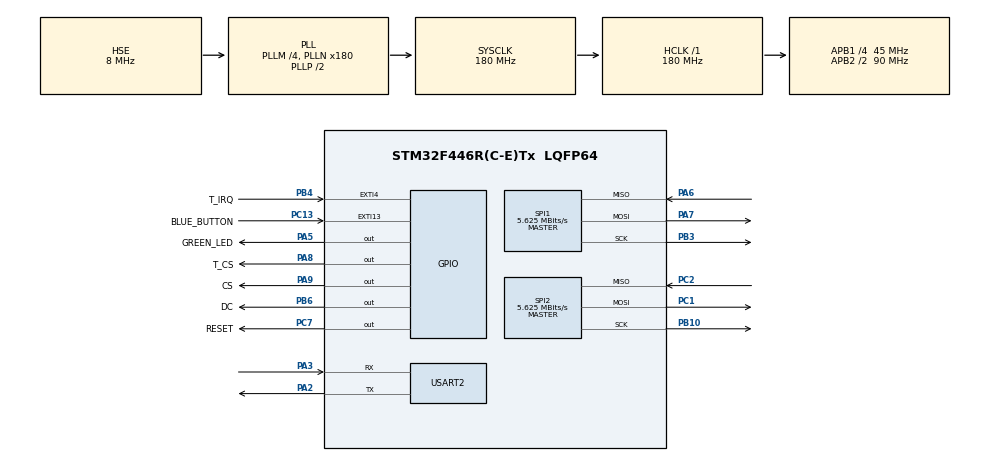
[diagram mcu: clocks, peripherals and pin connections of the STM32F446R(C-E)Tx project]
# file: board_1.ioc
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Dma.Request0=SPI1_TX
Dma.Request1=USART2_RX
Dma.Request2=USART2_TX
Dma.Request3=SPI2_RX
Dma.SPI1_TX.0.Direction=DMA_MEMORY_TO_PERIPH
Dma.SPI1_TX.0.FIFOMode=DMA_FIFOMODE_DISABLE
Dma.SPI1_TX.0.Instance=DMA2_Stream3
Dma.SPI1_TX.0.MemDataAlignment=DMA_MDATAALIGN_BYTE
Dma.SPI1_TX.0.MemInc=DMA_MINC_ENABLE
Dma.SPI1_TX.0.Mode=DMA_NORMAL
Dma.SPI1_TX.0.PeriphDataAlignment=DMA_PDATAALIGN_BYTE
Dma.SPI1_TX.0.PeriphInc=DMA_PINC_DISABLE
Dma.SPI1_TX.0.Priority=DMA_PRIORITY_LOW
Dma.SPI2_RX.3.Direction=DMA_PERIPH_TO_MEMORY
Dma.SPI2_RX.3.FIFOMode=DMA_FIFOMODE_DISABLE
Dma.SPI2_RX.3.Instance=DMA1_Stream3
Dma.SPI2_RX.3.MemDataAlignment=DMA_MDATAALIGN_BYTE
Dma.SPI2_RX.3.MemInc=DMA_MINC_ENABLE
Dma.SPI2_RX.3.Mode=DMA_NORMAL
Dma.SPI2_RX.3.PeriphDataAlignment=DMA_PDATAALIGN_BYTE
Dma.SPI2_RX.3.PeriphInc=DMA_PINC_DISABLE
Dma.SPI2_RX.3.Priority=DMA_PRIORITY_LOW
Dma.USART2_RX.1.Direction=DMA_PERIPH_TO_MEMORY
Dma.USART2_RX.1.FIFOMode=DMA_FIFOMODE_DISABLE
Dma.USART2_RX.1.Instance=DMA1_Stream5
Dma.USART2_RX.1.MemDataAlignment=DMA_MDATAALIGN_BYTE
Dma.USART2_RX.1.MemInc=DMA_MINC_ENABLE
Dma.USART2_RX.1.Mode=DMA_NORMAL
Dma.USART2_RX.1.PeriphDataAlignment=DMA_PDATAALIGN_BYTE
Dma.USART2_RX.1.PeriphInc=DMA_PINC_DISABLE
Dma.USART2_RX.1.Priority=DMA_PRIORITY_LOW
Dma.USART2_TX.2.Direction=DMA_MEMORY_TO_PERIPH
Dma.USART2_TX.2.FIFOMode=DMA_FIFOMODE_DISABLE
Dma.USART2_TX.2.Instance=DMA1_Stream6
Dma.USART2_TX.2.MemDataAlignment=DMA_MDATAALIGN_BYTE
Dma.USART2_TX.2.MemInc=DMA_MINC_ENABLE
Dma.USART2_TX.2.Mode=DMA_NORMAL
Dma.USART2_TX.2.PeriphDataAlignment=DMA_PDATAALIGN_BYTE
Dma.USART2_TX.2.PeriphInc=DMA_PINC_DISABLE
Dma.USART2_TX.2.Priority=DMA_PRIORITY_LOW
FREERTOS.Tasks01=normalTask,24,128,startNormalTask,Default,NULL,Dynamic,NULL,NULL
FREERTOS.configTOTAL_HEAP_SIZE=32768
Mcu.Family=STM32F4
Mcu.Name=STM32F446R(C-E)Tx
Mcu.Package=LQFP64
NVIC.DMA1_Stream3_IRQn=true\:5\:0\:false\:false\:true\:true\:false\:true\:true
NVIC.DMA1_Stream5_IRQn=true\:5\:0\:false\:false\:true\:true\:false\:true\:true
NVIC.DMA1_Stream6_IRQn=true\:5\:0\:false\:false\:true\:true\:false\:true\:true
NVIC.DMA2_Stream3_IRQn=true\:5\:0\:false\:false\:true\:true\:false\:true\:true
NVIC.EXTI15_10_IRQn=true\:5\:0\:false\:false\:true\:true\:true\:true\:true
NVIC.EXTI4_IRQn=true\:5\:0\:false\:false\:true\:true\:true\:true\:true
NVIC.PriorityGroup=NVIC_PRIORITYGROUP_4
NVIC.SPI1_IRQn=true\:5\:0\:false\:false\:true\:true\:true\:true\:true
NVIC.SPI2_IRQn=true\:5\:0\:false\:false\:true\:true\:true\:true\:true
NVIC.TIM6_DAC_IRQn=true\:15\:0\:false\:false\:true\:false\:false\:true\:true
NVIC.TimeBase=TIM6_DAC_IRQn
NVIC.TimeBaseIP=TIM6
NVIC.USART2_IRQn=true\:5\:0\:false\:false\:true\:true\:true\:true\:true
PA13.Mode=Serial_Wire
PA13.Signal=SYS_JTMS-SWDIO
PA14.Mode=Serial_Wire
PA14.Signal=SYS_JTCK-SWCLK
PA2.Mode=Asynchronous
PA2.Signal=USART2_TX
PA3.Mode=Asynchronous
PA3.Signal=USART2_RX
PA5.GPIO_Label=GREEN_LED
PA5.Signal=GPIO_Output
PA6.Mode=Full_Duplex_Master
PA6.Signal=SPI1_MISO
PA7.Mode=Full_Duplex_Master
PA7.Signal=SPI1_MOSI
PA8.GPIO_Label=T_CS
PA8.PinState=GPIO_PIN_SET
PA8.Signal=GPIO_Output
PA9.GPIO_Label=CS
PA9.PinState=GPIO_PIN_SET
PA9.Signal=GPIO_Output
PB10.Mode=Full_Duplex_Master
PB10.Signal=SPI2_SCK
PB3.Mode=Full_Duplex_Master
PB3.Signal=SPI1_SCK
PB4.GPIO_Label=T_IRQ
PB4.GPIO_ModeDefaultEXTI=GPIO_MODE_IT_FALLING
PB4.Signal=GPXTI4
PB6.GPIO_Label=DC
PB6.Signal=GPIO_Output
PC1.Mode=Full_Duplex_Master
PC1.Signal=SPI2_MOSI
PC13.GPIO_Label=BLUE_BUTTON
PC13.GPIO_ModeDefaultEXTI=GPIO_MODE_IT_FALLING
PC13.Signal=GPXTI13
PC14-OSC32_IN.Mode=LSE-External-Oscillator
PC14-OSC32_IN.Signal=RCC_OSC32_IN
PC15-OSC32_OUT.Mode=LSE-External-Oscillator
PC15-OSC32_OUT.Signal=RCC_OSC32_OUT
PC2.Mode=Full_Duplex_Master
PC2.Signal=SPI2_MISO
PC7.GPIO_Label=RESET
PC7.Signal=GPIO_Output
PH0-OSC_IN.Mode=HSE-External-Oscillator
PH0-OSC_IN.Signal=RCC_OSC_IN
PH1-OSC_OUT.Mode=HSE-External-Oscillator
PH1-OSC_OUT.Signal=RCC_OSC_OUT
ProjectManager.HeapSize=0x200
ProjectManager.StackSize=0x400
ProjectManager.TargetToolchain=CMake
RCC.AHBFreq_Value=180000000
RCC.APB1CLKDivider=RCC_HCLK_DIV4
RCC.APB1Freq_Value=45000000
RCC.APB1TimFreq_Value=90000000
RCC.APB2CLKDivider=RCC_HCLK_DIV2
RCC.APB2Freq_Value=90000000
RCC.APB2TimFreq_Value=180000000
RCC.CortexFreq_Value=180000000
RCC.HCLKFreq_Value=180000000
RCC.HSE_VALUE=8000000
RCC.PLLM=4
RCC.PLLN=180
RCC.PLLSourceVirtual=RCC_PLLSOURCE_HSE
RCC.RCC_RTC_Clock_SourceVirtual=RCC_RTCCLKSOURCE_LSE
RCC.SYSCLKFreq_VALUE=180000000
RCC.SYSCLKSource=RCC_SYSCLKSOURCE_PLLCLK
RCC.USBFreq_Value=180000000
RCC.VCOOutputFreq_Value=360000000
RTC.Date=12
RTC.Hours=9
RTC.Minutes=11
RTC.Month=RTC_MONTH_AUGUST
RTC.Year=25
SPI1.BaudRatePrescaler=SPI_BAUDRATEPRESCALER_16
SPI1.CalculateBaudRate=5.625 MBits/s
SPI1.Direction=SPI_DIRECTION_2LINES
SPI1.Mode=SPI_MODE_MASTER
SPI1.VirtualType=VM_MASTER
SPI2.BaudRatePrescaler=SPI_BAUDRATEPRESCALER_8
SPI2.CalculateBaudRate=5.625 MBits/s
SPI2.Direction=SPI_DIRECTION_2LINES
SPI2.Mode=SPI_MODE_MASTER
SPI2.VirtualType=VM_MASTER
STMicroelectronics.X-CUBE-TOUCHGFX.4.26.1.ApplicationCcGraphicsJjApplication=TouchGFXOoGenerator
STMicroelectronics.X-CUBE-TOUCHGFX.4.26.1.tgfx_block_size=10240
STMicroelectronics.X-CUBE-TOUCHGFX.4.26.1.tgfx_buffering_strategy=Partial
STMicroelectronics.X-CUBE-TOUCHGFX.4.26.1.tgfx_custom_height=240
STMicroelectronics.X-CUBE-TOUCHGFX.4.26.1.tgfx_custom_width=320
STMicroelectronics.X-CUBE-TOUCHGFX.4.26.1_IsPackSelfContextualization=true
USART2.VirtualMode=VM_ASYNC
VP_CRC_VS_CRC.Mode=CRC_Activate
VP_FREERTOS_VS_CMSIS_V2.Mode=CMSIS_V2
VP_IWDG_VS_IWDG.Mode=IWDG_Activate
VP_RTC_VS_RTC_Activate.Mode=RTC_Enabled
VP_RTC_VS_RTC_Calendar.Mode=RTC_Calendar
VP_STMicroelectronics.X-CUBE-TOUCHGFX_VS_GraphicsJjApplication_4.26.1.Mode=GraphicsJjApplication
VP_SYS_VS_tim6.Mode=TIM6
board=custom

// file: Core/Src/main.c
/* USER CODE BEGIN Header */
/**
  ******************************************************************************
  * @file           : main.c
  * @brief          : Main program body
  ******************************************************************************
  * @attention
  *
  * Copyright (c) 2025 STMicroelectronics.
  * All rights reserved.
  *
  * This software is licensed under terms that can be found in the LICENSE file
  * in the root directory of this software component.
  * If no LICENSE file comes with this software, it is provided AS-IS.
  *
  ******************************************************************************
  */
/* USER CODE END Header */
#include "main.h"
#include "cmsis_os.h"
#include "crc.h"
#include "dma.h"
#include "iwdg.h"
#include "rtc.h"
#include "spi.h"
#include "usart.h"
#include "gpio.h"
#include "app_touchgfx.h"

/* USER CODE BEGIN Includes */
#include "app_main.h"

/* USER CODE END Includes */

void SystemClock_Config(void);
void MX_FREERTOS_Init(void);

int main(void)
{

  /* USER CODE BEGIN 1 */
  // Super early blink to confirm code is running at all
  RCC->AHB1ENR |= RCC_AHB1ENR_GPIOAEN;
  GPIOA->MODER &= ~(3U << (5 * 2));
  GPIOA->MODER |= (1U << (5 * 2));
  for(int i=0; i<20; i++) {
    GPIOA->ODR ^= (1U << 5);
    for(volatile int j=0; j<100000; j++);
  }
  /* USER CODE END 1 */

  /* MCU Configuration--------------------------------------------------------*/

  /* Reset of all peripherals, Initializes the Flash interface and the Systick. */
  HAL_Init();

  /* Configure the system clock */
  SystemClock_Config();

  /* Initialize all configured peripherals */
  MX_GPIO_Init();
  MX_DMA_Init();
  MX_SPI1_Init();
  MX_RTC_Init();
  MX_SPI2_Init();
  MX_USART2_UART_Init();
  MX_CRC_Init();
  MX_IWDG_Init();
  MX_TouchGFX_Init();
  /* Call PreOsInit function */
  MX_TouchGFX_PreOSInit();
  /* USER CODE BEGIN 2 */
  /* DRV_Setup() runs at the top of the TouchGFX task (App/app_main.c), not
   * here: it uses HAL_Delay, and the first FreeRTOS API call (already made
   * above by MX_TouchGFX_Init) masks interrupts (BASEPRI) until
   * osKernelStart(), which freezes the HAL tick and deadlocks any pre-kernel
   * HAL_Delay. */
  /* USER CODE END 2 */

  /* Init scheduler */
  osKernelInitialize();  /* Call init function for freertos objects (in cmsis_os2.c) */
  MX_FREERTOS_Init();

  /* Start scheduler */
  osKernelStart();

  /* We should never get here as control is now taken by the scheduler */

  /* Infinite loop */
  while (1)
  {

  }
}

void SystemClock_Config(void)
{
  RCC_OscInitTypeDef RCC_OscInitStruct = {0};
  RCC_ClkInitTypeDef RCC_ClkInitStruct = {0};

  /** Configure the main internal regulator output voltage
  */
  __HAL_RCC_PWR_CLK_ENABLE();
  __HAL_PWR_VOLTAGESCALING_CONFIG(PWR_REGULATOR_VOLTAGE_SCALE1);

  /** Initializes the RCC Oscillators according to the specified parameters
  * in the RCC_OscInitTypeDef structure.
  */
  RCC_OscInitStruct.OscillatorType = RCC_OSCILLATORTYPE_LSI|RCC_OSCILLATORTYPE_HSE
                              |RCC_OSCILLATORTYPE_LSE;
  RCC_OscInitStruct.HSEState = RCC_HSE_ON;
  RCC_OscInitStruct.LSEState = RCC_LSE_ON;
  RCC_OscInitStruct.LSIState = RCC_LSI_ON;
  RCC_OscInitStruct.PLL.PLLState = RCC_PLL_ON;
  RCC_OscInitStruct.PLL.PLLSource = RCC_PLLSOURCE_HSE;
  RCC_OscInitStruct.PLL.PLLM = 4;
  RCC_OscInitStruct.PLL.PLLN = 180;
  RCC_OscInitStruct.PLL.PLLP = RCC_PLLP_DIV2;
  RCC_OscInitStruct.PLL.PLLQ = 2;
  RCC_OscInitStruct.PLL.PLLR = 2;
  if (HAL_RCC_OscConfig(&RCC_OscInitStruct) != HAL_OK)
  {
    Error_Handler();
  }

  /** Activate the Over-Drive mode
  */
  if (HAL_PWREx_EnableOverDrive() != HAL_OK)
  {
    Error_Handler();
  }

  /** Initializes the CPU, AHB and APB buses clocks
  */
  RCC_ClkInitStruct.ClockType = RCC_CLOCKTYPE_HCLK|RCC_CLOCKTYPE_SYSCLK
                              |RCC_CLOCKTYPE_PCLK1|RCC_CLOCKTYPE_PCLK2;
  RCC_ClkInitStruct.SYSCLKSource = RCC_SYSCLKSOURCE_PLLCLK;
  RCC_ClkInitStruct.AHBCLKDivider = RCC_SYSCLK_DIV1;
  RCC_ClkInitStruct.APB1CLKDivider = RCC_HCLK_DIV4;
  RCC_ClkInitStruct.APB2CLKDivider = RCC_HCLK_DIV2;

  if (HAL_RCC_ClockConfig(&RCC_ClkInitStruct, FLASH_LATENCY_5) != HAL_OK)
  {
    Error_Handler();
  }
}

void HAL_TIM_PeriodElapsedCallback(TIM_HandleTypeDef *htim)
{
  if (htim->Instance == TIM6)
  {
    HAL_IncTick();
  }
}

void Error_Handler(void)
{
  __disable_irq();
  while (1)
  {
  }
}

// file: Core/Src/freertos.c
/* USER CODE BEGIN Header */
/**
  ******************************************************************************
  * File Name          : freertos.c
  * Description        : Code for freertos applications
  ******************************************************************************
  * @attention
  *
  * Copyright (c) 2025 STMicroelectronics.
  * All rights reserved.
  *
  * This software is licensed under terms that can be found in the LICENSE file
  * in the root directory of this software component.
  * If no LICENSE file comes with this software, it is provided AS-IS.
  *
  ******************************************************************************
  */
/* USER CODE END Header */

#include "FreeRTOS.h"
#include "task.h"
#include "main.h"
#include "cmsis_os.h"

/* USER CODE BEGIN Includes */
#include "app_main.h"
/* USER CODE END Includes */

/* Definitions for normalTask */
osThreadId_t normalTaskHandle;
const osThreadAttr_t normalTask_attributes = {
  .name = "normalTask",
  .stack_size = 128 * 4,
  .priority = (osPriority_t) osPriorityNormal,
};

void startNormalTask(void *argument);

void MX_FREERTOS_Init(void); /* (MISRA C 2004 rule 8.1) */

void MX_FREERTOS_Init(void) {

  /* Create the thread(s) */
  /* creation of normalTask */
  normalTaskHandle = osThreadNew(startNormalTask, NULL, &normalTask_attributes);

  /* USER CODE BEGIN RTOS_THREADS */
  /* add threads, ... */
  App_CreateTasks();
  /* USER CODE END RTOS_THREADS */

}

void startNormalTask(void *argument)
{
  for(;;)
  {
    osDelay(1);
  }
}

/* USER CODE BEGIN Application */

/* configCHECK_FOR_STACK_OVERFLOW / configUSE_MALLOC_FAILED_HOOK are enabled
 * in FreeRTOSConfig.h so these land in Error_Handler() (a debugger breakpoint
 * away from the culprit) instead of corrupting adjacent memory silently. */
void vApplicationStackOverflowHook(TaskHandle_t xTask, char *pcTaskName)
{
  (void)xTask;
  (void)pcTaskName;
  Error_Handler();
}

void vApplicationMallocFailedHook(void)
{
  Error_Handler();
}

/* USER CODE END Application */
